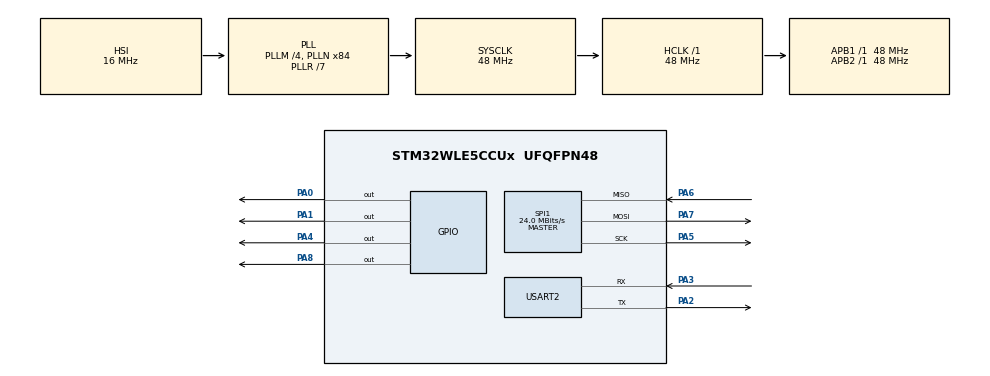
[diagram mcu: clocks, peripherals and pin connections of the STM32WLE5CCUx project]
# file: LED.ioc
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Mcu.Family=STM32WL
Mcu.Name=STM32WLE5CCUx
Mcu.Package=UFQFPN48
NVIC.PriorityGroup=NVIC_PRIORITYGROUP_4
PA0.Signal=GPIO_Output
PA1.Signal=GPIO_Output
PA2.Mode=Asynchronous
PA2.Signal=USART2_TX
PA3.Mode=Asynchronous
PA3.Signal=USART2_RX
PA4.Signal=GPIO_Output
PA5.Mode=Full_Duplex_Master
PA5.Signal=SPI1_SCK
PA6.Mode=Full_Duplex_Master
PA6.Signal=SPI1_MISO
PA7.Mode=Full_Duplex_Master
PA7.Signal=SPI1_MOSI
PA8.PinState=GPIO_PIN_SET
PA8.Signal=GPIO_Output
ProjectManager.HeapSize=0x200
ProjectManager.StackSize=0x400
ProjectManager.TargetToolchain=MDK-ARM V5.27
RCC.AHBFreq_Value=48000000
RCC.APB1Freq_Value=48000000
RCC.APB1TimFreq_Value=48000000
RCC.APB2Freq_Value=48000000
RCC.APB2TimFreq_Value=48000000
RCC.APB3Freq_Value=48000000
RCC.CortexFreq_Value=48000000
RCC.HCLKFreq_Value=48000000
RCC.HSE_VALUE=8000000
RCC.HSI_VALUE=16000000
RCC.LSE_VALUE=32768
RCC.PLLM=RCC_PLLM_DIV4
RCC.PLLN=84
RCC.PLLR=RCC_PLLR_DIV7
RCC.PLLSourceVirtual=RCC_PLLSOURCE_HSI
RCC.SYSCLKFreq_VALUE=48000000
RCC.SYSCLKSource=RCC_SYSCLKSOURCE_PLLCLK
RCC.VCOOutputFreq_Value=336000000
SPI1.CalculateBaudRate=24.0 MBits/s
SPI1.DataSize=SPI_DATASIZE_8BIT
SPI1.Direction=SPI_DIRECTION_2LINES
SPI1.Mode=SPI_MODE_MASTER
SPI1.VirtualType=VM_MASTER
USART2.VirtualMode-Asynchronous=VM_ASYNC
board=custom

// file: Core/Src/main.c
/* USER CODE BEGIN Header */
/**
  ******************************************************************************
  * @file           : main.c
  * @brief          : Main program body
  ******************************************************************************
  * @attention
  *
  * <h2><center>&copy; Copyright (c) 2021 STMicroelectronics.
  * All rights reserved.</center></h2>
  *
  * This software component is licensed by ST under BSD 3-Clause license,
  * the "License"; You may not use this file except in compliance with the
  * License. You may obtain a copy of the License at:
  *                        opensource.org/licenses/BSD-3-Clause
  *
  ******************************************************************************
  */
/* USER CODE END Header */
#include "main.h"
#include "spi.h"
#include "usart.h"
#include "gpio.h"

/* USER CODE BEGIN Includes */
#include "stdio.h"
/* USER CODE END Includes */

void SystemClock_Config(void);

int main(void)
{

  /* MCU Configuration--------------------------------------------------------*/

  /* Reset of all peripherals, Initializes the Flash interface and the Systick. */
  HAL_Init();

  /* Configure the system clock */
  SystemClock_Config();

  /* Initialize all configured peripherals */
  MX_GPIO_Init();
  MX_USART2_UART_Init();
  MX_SPI1_Init();

  /* Infinite loop */
  while (1)
  {

    /* USER CODE BEGIN 3 */

	  HAL_GPIO_TogglePin(GPIOA,GPIO_PIN_0);
	  HAL_GPIO_TogglePin(GPIOA,GPIO_PIN_1);
	  //HAL_Delay(100);
	  //printf("Hello\r\n");
	  DG_Test();
  }
  /* USER CODE END 3 */
}

void SystemClock_Config(void)
{
  RCC_OscInitTypeDef RCC_OscInitStruct = {0};
  RCC_ClkInitTypeDef RCC_ClkInitStruct = {0};

  /** Configure the main internal regulator output voltage
  */
  __HAL_PWR_VOLTAGESCALING_CONFIG(PWR_REGULATOR_VOLTAGE_SCALE1);
  /** Initializes the CPU, AHB and APB busses clocks
  */
  RCC_OscInitStruct.OscillatorType = RCC_OSCILLATORTYPE_HSI;
  RCC_OscInitStruct.HSIState = RCC_HSI_ON;
  RCC_OscInitStruct.HSICalibrationValue = RCC_HSICALIBRATION_DEFAULT;
  RCC_OscInitStruct.PLL.PLLState = RCC_PLL_ON;
  RCC_OscInitStruct.PLL.PLLSource = RCC_PLLSOURCE_HSI;
  RCC_OscInitStruct.PLL.PLLM = RCC_PLLM_DIV4;
  RCC_OscInitStruct.PLL.PLLN = 84;
  RCC_OscInitStruct.PLL.PLLP = RCC_PLLP_DIV2;
  RCC_OscInitStruct.PLL.PLLR = RCC_PLLR_DIV7;
  RCC_OscInitStruct.PLL.PLLQ = RCC_PLLQ_DIV2;
  if (HAL_RCC_OscConfig(&RCC_OscInitStruct) != HAL_OK)
  {
    Error_Handler();
  }
  /** Configure the SYSCLKSource, HCLK, PCLK1 and PCLK2 clocks dividers
  */
  RCC_ClkInitStruct.ClockType = RCC_CLOCKTYPE_HCLK3|RCC_CLOCKTYPE_HCLK
                              |RCC_CLOCKTYPE_SYSCLK|RCC_CLOCKTYPE_PCLK1
                              |RCC_CLOCKTYPE_PCLK2;
  RCC_ClkInitStruct.SYSCLKSource = RCC_SYSCLKSOURCE_PLLCLK;
  RCC_ClkInitStruct.AHBCLKDivider = RCC_SYSCLK_DIV1;
  RCC_ClkInitStruct.APB1CLKDivider = RCC_HCLK_DIV1;
  RCC_ClkInitStruct.APB2CLKDivider = RCC_HCLK_DIV1;
  RCC_ClkInitStruct.AHBCLK3Divider = RCC_SYSCLK_DIV1;

  if (HAL_RCC_ClockConfig(&RCC_ClkInitStruct, FLASH_LATENCY_2) != HAL_OK)
  {
    Error_Handler();
  }
}

void Error_Handler(void)
{
  __disable_irq();
  while (1)
  {
  }
}

/************************ (C) COPYRIGHT STMicroelectronics *****END OF FILE****/
